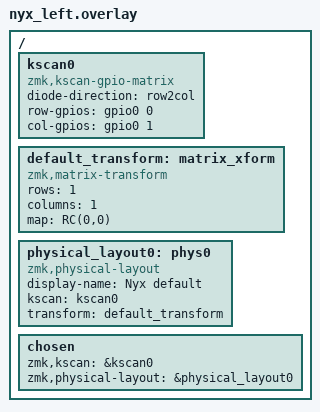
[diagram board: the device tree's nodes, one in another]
/* Skeleton overlay — replace row/col pins later */
#include <dt-bindings/zmk/matrix_transform.h>

/ {
    kscan0: kscan0 {
        compatible = "zmk,kscan-gpio-matrix";
        diode-direction = "row2col";
        row-gpios = < &gpio0 0 (GPIO_ACTIVE_HIGH | GPIO_PULL_DOWN) >; /* TODO: real pins */
        col-gpios = < &gpio0 1 GPIO_ACTIVE_HIGH >;                   /* TODO: real pins */
    };

    default_transform: matrix_xform {
        compatible = "zmk,matrix-transform";
        rows = <1>;   /* update when you know row count */
        columns = <1>;/* update when you know column count */
        map = < RC(0,0) >;  /* expand later */
    };

    physical_layout0: phys0 {
        compatible = "zmk,physical-layout";
        display-name = "Nyx default";
        kscan = <&kscan0>;
        transform = <&default_transform>;
    };

    chosen {
        zmk,kscan = &kscan0;
        zmk,physical-layout = &physical_layout0;
    };
};
